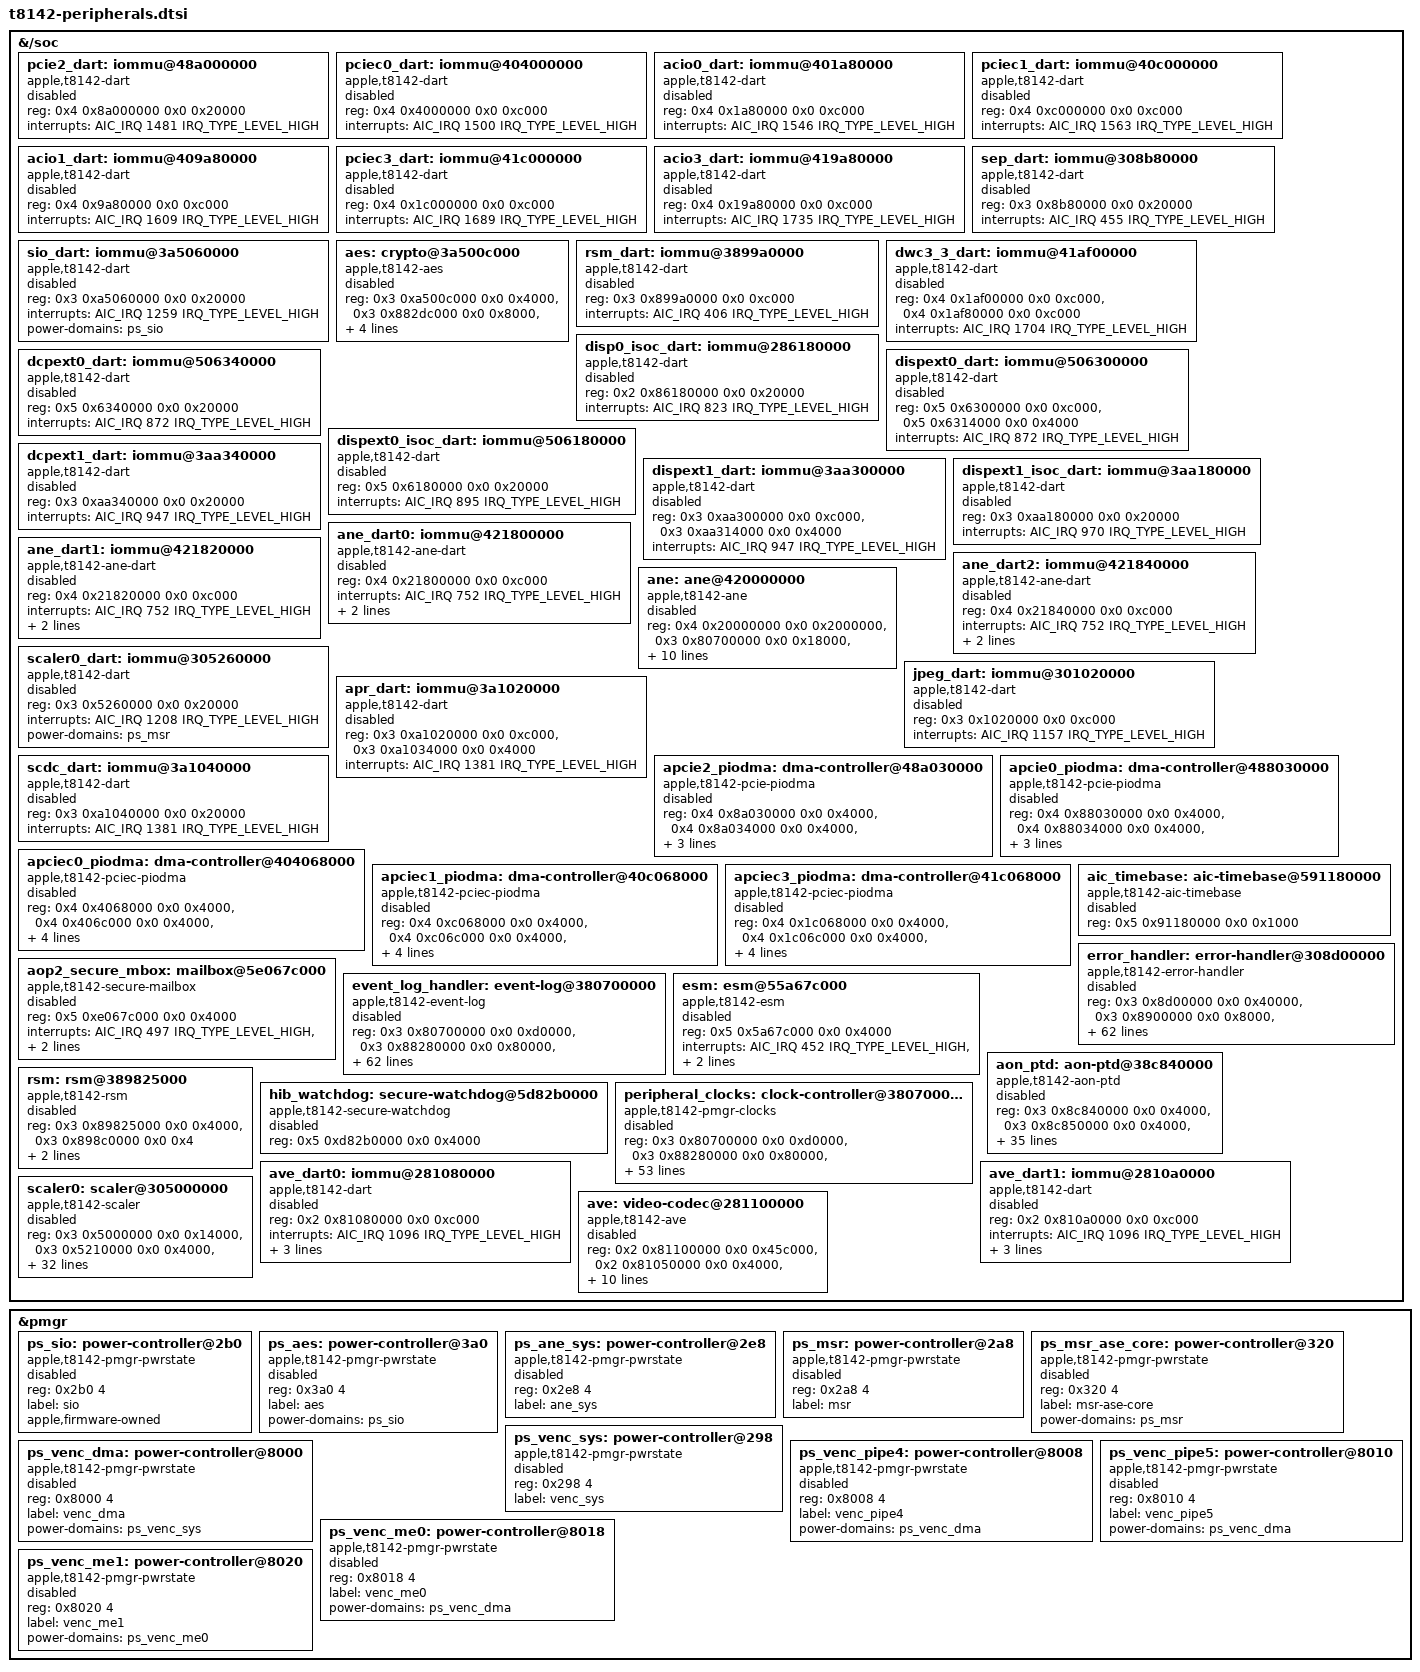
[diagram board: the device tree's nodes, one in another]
// SPDX-License-Identifier: GPL-2.0+ OR MIT
/* Shared SoC resources; firmware ownership and enables need qualification. */

&{/soc} {
	pcie2_dart: iommu@48a000000 {
		compatible = "apple,t8142-dart", "apple,t8110-dart";
		reg = <0x4 0x8a000000 0x0 0x20000>;
		interrupts = <AIC_IRQ 1481 IRQ_TYPE_LEVEL_HIGH>;
		#iommu-cells = <1>;
		status = "disabled";
	};

	pciec0_dart: iommu@404000000 {
		compatible = "apple,t8142-dart", "apple,t8110-dart";
		reg = <0x4 0x4000000 0x0 0xc000>;
		interrupts = <AIC_IRQ 1500 IRQ_TYPE_LEVEL_HIGH>;
		#iommu-cells = <1>;
		status = "disabled";
	};

	acio0_dart: iommu@401a80000 {
		compatible = "apple,t8142-dart", "apple,t8110-dart";
		reg = <0x4 0x1a80000 0x0 0xc000>;
		interrupts = <AIC_IRQ 1546 IRQ_TYPE_LEVEL_HIGH>;
		#iommu-cells = <1>;
		status = "disabled";
	};

	pciec1_dart: iommu@40c000000 {
		compatible = "apple,t8142-dart", "apple,t8110-dart";
		reg = <0x4 0xc000000 0x0 0xc000>;
		interrupts = <AIC_IRQ 1563 IRQ_TYPE_LEVEL_HIGH>;
		#iommu-cells = <1>;
		status = "disabled";
	};

	acio1_dart: iommu@409a80000 {
		compatible = "apple,t8142-dart", "apple,t8110-dart";
		reg = <0x4 0x9a80000 0x0 0xc000>;
		interrupts = <AIC_IRQ 1609 IRQ_TYPE_LEVEL_HIGH>;
		#iommu-cells = <1>;
		status = "disabled";
	};

	pciec3_dart: iommu@41c000000 {
		compatible = "apple,t8142-dart", "apple,t8110-dart";
		reg = <0x4 0x1c000000 0x0 0xc000>;
		interrupts = <AIC_IRQ 1689 IRQ_TYPE_LEVEL_HIGH>;
		#iommu-cells = <1>;
		status = "disabled";
	};

	acio3_dart: iommu@419a80000 {
		compatible = "apple,t8142-dart", "apple,t8110-dart";
		reg = <0x4 0x19a80000 0x0 0xc000>;
		interrupts = <AIC_IRQ 1735 IRQ_TYPE_LEVEL_HIGH>;
		#iommu-cells = <1>;
		status = "disabled";
	};

	sep_dart: iommu@308b80000 {
		compatible = "apple,t8142-dart", "apple,t8110-dart";
		reg = <0x3 0x8b80000 0x0 0x20000>;
		interrupts = <AIC_IRQ 455 IRQ_TYPE_LEVEL_HIGH>;
		#iommu-cells = <1>;
		status = "disabled";
	};

	sio_dart: iommu@3a5060000 {
		compatible = "apple,t8142-dart", "apple,t8110-dart";
		reg = <0x3 0xa5060000 0x0 0x20000>;
		interrupts = <AIC_IRQ 1259 IRQ_TYPE_LEVEL_HIGH>;
		#iommu-cells = <1>;
		power-domains = <&ps_sio>;
		status = "disabled";
	};

	/*
	 * ADT /arm-io/aes (aes,s8000, aes-version 5): the engine, shared control
	 * and auxiliary control windows; DART-SIO mapper-aes is stream 1.
	 */
	aes: crypto@3a500c000 {
		compatible = "apple,t8142-aes", "apple,aes";
		reg = <0x3 0xa500c000 0x0 0x4000>,
		      <0x3 0x882dc000 0x0 0x8000>,
		      <0x3 0x88078000 0x0 0x4000>;
		interrupts = <AIC_IRQ 1246 IRQ_TYPE_LEVEL_HIGH>;
		power-domains = <&ps_aes>;
		iommus = <&sio_dart 1>;
		status = "disabled";
	};

	rsm_dart: iommu@3899a0000 {
		compatible = "apple,t8142-dart", "apple,t8110-dart";
		reg = <0x3 0x899a0000 0x0 0xc000>;
		interrupts = <AIC_IRQ 406 IRQ_TYPE_LEVEL_HIGH>;
		#iommu-cells = <1>;
		status = "disabled";
	};

	dwc3_3_dart: iommu@41af00000 {
		compatible = "apple,t8142-dart", "apple,t8110-dart";
		reg = <0x4 0x1af00000 0x0 0xc000>,
		      <0x4 0x1af80000 0x0 0xc000>;
		interrupts = <AIC_IRQ 1704 IRQ_TYPE_LEVEL_HIGH>;
		#iommu-cells = <1>;
		status = "disabled";
	};

	disp0_isoc_dart: iommu@286180000 {
		compatible = "apple,t8142-dart", "apple,t8110-dart";
		reg = <0x2 0x86180000 0x0 0x20000>;
		interrupts = <AIC_IRQ 823 IRQ_TYPE_LEVEL_HIGH>;
		#iommu-cells = <1>;
		status = "disabled";
	};

	dcpext0_dart: iommu@506340000 {
		compatible = "apple,t8142-dart", "apple,t8110-dart";
		reg = <0x5 0x6340000 0x0 0x20000>;
		interrupts = <AIC_IRQ 872 IRQ_TYPE_LEVEL_HIGH>;
		#iommu-cells = <1>;
		status = "disabled";
	};

	dispext0_dart: iommu@506300000 {
		compatible = "apple,t8142-dart", "apple,t8110-dart";
		reg = <0x5 0x6300000 0x0 0xc000>,
		      <0x5 0x6314000 0x0 0x4000>;
		interrupts = <AIC_IRQ 872 IRQ_TYPE_LEVEL_HIGH>;
		#iommu-cells = <1>;
		status = "disabled";
	};

	dispext0_isoc_dart: iommu@506180000 {
		compatible = "apple,t8142-dart", "apple,t8110-dart";
		reg = <0x5 0x6180000 0x0 0x20000>;
		interrupts = <AIC_IRQ 895 IRQ_TYPE_LEVEL_HIGH>;
		#iommu-cells = <1>;
		status = "disabled";
	};

	dcpext1_dart: iommu@3aa340000 {
		compatible = "apple,t8142-dart", "apple,t8110-dart";
		reg = <0x3 0xaa340000 0x0 0x20000>;
		interrupts = <AIC_IRQ 947 IRQ_TYPE_LEVEL_HIGH>;
		#iommu-cells = <1>;
		status = "disabled";
	};

	dispext1_dart: iommu@3aa300000 {
		compatible = "apple,t8142-dart", "apple,t8110-dart";
		reg = <0x3 0xaa300000 0x0 0xc000>,
		      <0x3 0xaa314000 0x0 0x4000>;
		interrupts = <AIC_IRQ 947 IRQ_TYPE_LEVEL_HIGH>;
		#iommu-cells = <1>;
		status = "disabled";
	};

	dispext1_isoc_dart: iommu@3aa180000 {
		compatible = "apple,t8142-dart", "apple,t8110-dart";
		reg = <0x3 0xaa180000 0x0 0x20000>;
		interrupts = <AIC_IRQ 970 IRQ_TYPE_LEVEL_HIGH>;
		#iommu-cells = <1>;
		status = "disabled";
	};

	/*
	 * The Neural Engine's three DARTs (ADT dart-ane, one interrupt for all):
	 * revision 0x204, 16 streams; SIDs 1-7 are the exclave's and 10/13
	 * bypass. The cold profile leaves every inherited stream alone and
	 * gives the kernel only SID0.
	 */
	ane_dart0: iommu@421800000 {
		compatible = "apple,t8142-ane-dart", "apple,t8142-dart",
			     "apple,t8110-dart";
		reg = <0x4 0x21800000 0x0 0xc000>;
		#iommu-cells = <1>;
		interrupts = <AIC_IRQ 752 IRQ_TYPE_LEVEL_HIGH>;
		power-domains = <&ps_ane_sys>;
		/* The firmware DVAs reach 0x100_xxxx_xxxx. */
		apple,dma-range = <0x0 0x0 0x400 0x0>;
		status = "disabled";
	};

	ane_dart1: iommu@421820000 {
		compatible = "apple,t8142-ane-dart", "apple,t8142-dart",
			     "apple,t8110-dart";
		reg = <0x4 0x21820000 0x0 0xc000>;
		#iommu-cells = <1>;
		interrupts = <AIC_IRQ 752 IRQ_TYPE_LEVEL_HIGH>;
		power-domains = <&ps_ane_sys>;
		apple,dma-range = <0x0 0x0 0x400 0x0>;
		status = "disabled";
	};

	ane_dart2: iommu@421840000 {
		compatible = "apple,t8142-ane-dart", "apple,t8142-dart",
			     "apple,t8110-dart";
		reg = <0x4 0x21840000 0x0 0xc000>;
		#iommu-cells = <1>;
		interrupts = <AIC_IRQ 752 IRQ_TYPE_LEVEL_HIGH>;
		power-domains = <&ps_ane_sys>;
		apple,dma-range = <0x0 0x0 0x400 0x0>;
		status = "disabled";
	};

	/*
	 * The Neural Engine (ADT /arm-io/ane, "ane,t8132exclave", ane-type 0x210):
	 * the H17 engine, exclave-assigned, with firmware that iBoot preloads; the
	 * boot loader hands the preload over as firmware-text and firmware-data.
	 * PWGATE is the ADT's reg[2] (PMGR +0x24000) + 0x3640, measured under
	 * macOS 27.2.1.
	 */
	ane: ane@420000000 {
		compatible = "apple,t8142-ane";
		reg = <0x4 0x20000000 0x0 0x2000000>,
		      <0x3 0x80700000 0x0 0x18000>,
		      <0x3 0x80727640 0x0 0x34>;
		reg-names = "engine", "pmgr", "pwgate";
		interrupts = <AIC_IRQ 751 IRQ_TYPE_LEVEL_HIGH>,
			     <AIC_IRQ 764 IRQ_TYPE_LEVEL_HIGH>;
		iommus = <&ane_dart0 0>, <&ane_dart1 0>, <&ane_dart2 0>;
		power-domains = <&ps_ane_sys>;
		apple,firmware-preloaded;
		apple,firmware-iovas = /bits/ 64 <0x10000000000 0x100000c0000>;
		/* Inclusive SID0 identity windows from the ADT's dart-ane dapf-instance-0. */
		apple,dapf-ranges = /bits/ 64 <0x4a1668000 0x4a1668003
					     0x3807002e8 0x3807002eb
					     0x38070c008 0x38070c00b
					     0x582668000 0x582668003>;
		status = "disabled";
	};

	scaler0_dart: iommu@305260000 {
		compatible = "apple,t8142-dart", "apple,t8110-dart";
		reg = <0x3 0x5260000 0x0 0x20000>;
		interrupts = <AIC_IRQ 1208 IRQ_TYPE_LEVEL_HIGH>;
		/* No DART gate in the ADT: powered with its engine. */
		power-domains = <&ps_msr>;
		#iommu-cells = <1>;
		status = "disabled";
	};

	jpeg_dart: iommu@301020000 {
		compatible = "apple,t8142-dart", "apple,t8110-dart";
		reg = <0x3 0x1020000 0x0 0xc000>;
		interrupts = <AIC_IRQ 1157 IRQ_TYPE_LEVEL_HIGH>;
		#iommu-cells = <1>;
		status = "disabled";
	};

	apr_dart: iommu@3a1020000 {
		compatible = "apple,t8142-dart", "apple,t8110-dart";
		reg = <0x3 0xa1020000 0x0 0xc000>,
		      <0x3 0xa1034000 0x0 0x4000>;
		interrupts = <AIC_IRQ 1381 IRQ_TYPE_LEVEL_HIGH>;
		#iommu-cells = <1>;
		status = "disabled";
	};

	scdc_dart: iommu@3a1040000 {
		compatible = "apple,t8142-dart", "apple,t8110-dart";
		reg = <0x3 0xa1040000 0x0 0x20000>;
		interrupts = <AIC_IRQ 1381 IRQ_TYPE_LEVEL_HIGH>;
		#iommu-cells = <1>;
		status = "disabled";
	};

	apcie2_piodma: dma-controller@48a030000 {
		compatible = "apple,t8142-pcie-piodma", "apple,pcie-piodma";
		reg = <0x4 0x8a030000 0x0 0x4000>,
		      <0x4 0x8a034000 0x0 0x4000>,
		      <0x4 0x8a038000 0x0 0x4000>;
		interrupts = <AIC_IRQ 1482 IRQ_TYPE_LEVEL_HIGH>;
		iommus = <&pcie2_dart 17>;
		status = "disabled";
	};

	apcie0_piodma: dma-controller@488030000 {
		compatible = "apple,t8142-pcie-piodma", "apple,pcie-piodma";
		reg = <0x4 0x88030000 0x0 0x4000>,
		      <0x4 0x88034000 0x0 0x4000>,
		      <0x4 0x88038000 0x0 0x4000>;
		interrupts = <AIC_IRQ 1464 IRQ_TYPE_LEVEL_HIGH>;
		iommus = <&pcie0_dart 17>;
		status = "disabled";
	};

	apciec0_piodma: dma-controller@404068000 {
		compatible = "apple,t8142-pciec-piodma", "apple,pciec-piodma";
		reg = <0x4 0x4068000 0x0 0x4000>,
		      <0x4 0x406c000 0x0 0x4000>,
		      <0x4 0x4070000 0x0 0x4000>,
		      <0x4 0x403c000 0x0 0x4000>;
		interrupts = <AIC_IRQ 1501 IRQ_TYPE_LEVEL_HIGH>;
		iommus = <&pciec0_dart 254>;
		status = "disabled";
	};

	apciec1_piodma: dma-controller@40c068000 {
		compatible = "apple,t8142-pciec-piodma", "apple,pciec-piodma";
		reg = <0x4 0xc068000 0x0 0x4000>,
		      <0x4 0xc06c000 0x0 0x4000>,
		      <0x4 0xc070000 0x0 0x4000>,
		      <0x4 0xc03c000 0x0 0x4000>;
		interrupts = <AIC_IRQ 1564 IRQ_TYPE_LEVEL_HIGH>;
		iommus = <&pciec1_dart 254>;
		status = "disabled";
	};

	apciec3_piodma: dma-controller@41c068000 {
		compatible = "apple,t8142-pciec-piodma", "apple,pciec-piodma";
		reg = <0x4 0x1c068000 0x0 0x4000>,
		      <0x4 0x1c06c000 0x0 0x4000>,
		      <0x4 0x1c070000 0x0 0x4000>,
		      <0x4 0x1c03c000 0x0 0x4000>;
		interrupts = <AIC_IRQ 1690 IRQ_TYPE_LEVEL_HIGH>;
		iommus = <&pciec3_dart 254>;
		status = "disabled";
	};

	aic_timebase: aic-timebase@591180000 {
		compatible = "apple,t8142-aic-timebase", "apple,aic-timebase";
		reg = <0x5 0x91180000 0x0 0x1000>;
		status = "disabled";
	};

	error_handler: error-handler@308d00000 {
		compatible = "apple,t8142-error-handler", "apple,soc-error-handler";
		reg = <0x3 0x8d00000 0x0 0x40000>,
		      <0x3 0x8900000 0x0 0x8000>,
		      <0x3 0x80000000 0x0 0x3c000>,
		      <0x3 0x80728000 0x0 0x4000>,
		      <0x3 0x80768000 0x0 0x4000>,
		      <0x3 0x882c8000 0x0 0x4000>,
		      <0x3 0x82000000 0x0 0x1000000>,
		      <0x3 0x803d0000 0x0 0x4000>,
		      <0x2 0x20000000 0x0 0x140000>,
		      <0x2 0x21000000 0x0 0x3c000>,
		      <0x2 0x21200000 0x0 0x3c000>,
		      <0x2 0x21400000 0x0 0x3c000>,
		      <0x2 0x21600000 0x0 0x3c000>,
		      <0x2 0x21800000 0x0 0x3c000>,
		      <0x2 0x21a00000 0x0 0x3c000>,
		      <0x2 0x21c00000 0x0 0x3c000>,
		      <0x2 0x21e00000 0x0 0x3c000>,
		      <0x2 0x4f000000 0x0 0x8000>,
		      <0x2 0x50000000 0x0 0x8000>,
		      <0x2 0x51000000 0x0 0x8000>,
		      <0x2 0x52000000 0x0 0x8000>,
		      <0x2 0x53000000 0x0 0x8000>,
		      <0x2 0x54000000 0x0 0x8000>,
		      <0x2 0x55000000 0x0 0x8000>,
		      <0x2 0x56000000 0x0 0x8000>,
		      <0x2 0x5f000000 0x0 0x8000>,
		      <0x2 0x6f000000 0x0 0x8000>,
		      <0x2 0x57000000 0x0 0x1000000>,
		      <0x2 0x58000000 0x0 0x1000000>,
		      <0x2 0x59000000 0x0 0x1000000>,
		      <0x3 0x80770000 0x0 0x4000>,
		      <0x3 0x80771000 0x0 0x4000>,
		      <0x2 0x5b000000 0x0 0x24000>;
		interrupts = <AIC_IRQ 454 IRQ_TYPE_LEVEL_HIGH>,
		             <AIC_IRQ 457 IRQ_TYPE_LEVEL_HIGH>,
		             <AIC_IRQ 453 IRQ_TYPE_LEVEL_HIGH>,
		             <AIC_IRQ 1069 IRQ_TYPE_LEVEL_HIGH>,
		             <AIC_IRQ 371 IRQ_TYPE_LEVEL_HIGH>,
		             <AIC_IRQ 373 IRQ_TYPE_LEVEL_HIGH>,
		             <AIC_IRQ 375 IRQ_TYPE_LEVEL_HIGH>,
		             <AIC_IRQ 377 IRQ_TYPE_LEVEL_HIGH>,
		             <AIC_IRQ 379 IRQ_TYPE_LEVEL_HIGH>,
		             <AIC_IRQ 382 IRQ_TYPE_LEVEL_HIGH>,
		             <AIC_IRQ 385 IRQ_TYPE_LEVEL_HIGH>,
		             <AIC_IRQ 388 IRQ_TYPE_LEVEL_HIGH>,
		             <AIC_IRQ 391 IRQ_TYPE_LEVEL_HIGH>,
		             <AIC_IRQ 394 IRQ_TYPE_LEVEL_HIGH>,
		             <AIC_IRQ 397 IRQ_TYPE_LEVEL_HIGH>,
		             <AIC_IRQ 400 IRQ_TYPE_LEVEL_HIGH>,
		             <AIC_IRQ 187 IRQ_TYPE_LEVEL_HIGH>,
		             <AIC_IRQ 188 IRQ_TYPE_LEVEL_HIGH>,
		             <AIC_IRQ 189 IRQ_TYPE_LEVEL_HIGH>,
		             <AIC_IRQ 190 IRQ_TYPE_LEVEL_HIGH>,
		             <AIC_IRQ 191 IRQ_TYPE_LEVEL_HIGH>,
		             <AIC_IRQ 192 IRQ_TYPE_LEVEL_HIGH>,
		             <AIC_IRQ 193 IRQ_TYPE_LEVEL_HIGH>,
		             <AIC_IRQ 194 IRQ_TYPE_LEVEL_HIGH>,
		             <AIC_IRQ 201 IRQ_TYPE_LEVEL_HIGH>,
		             <AIC_IRQ 200 IRQ_TYPE_LEVEL_HIGH>,
		             <AIC_IRQ 195 IRQ_TYPE_LEVEL_HIGH>,
		             <AIC_IRQ 196 IRQ_TYPE_LEVEL_HIGH>,
		             <AIC_IRQ 197 IRQ_TYPE_LEVEL_HIGH>,
		             <AIC_IRQ 311 IRQ_TYPE_LEVEL_HIGH>,
		             <AIC_IRQ 198 IRQ_TYPE_LEVEL_HIGH>;
		/* Shared status windows do not grant AP ownership. */
		status = "disabled";
	};

	aop2_secure_mbox: mailbox@5e067c000 {
		compatible = "apple,t8142-secure-mailbox", "apple,secure-mailbox";
		reg = <0x5 0xe067c000 0x0 0x4000>;
		interrupts = <AIC_IRQ 497 IRQ_TYPE_LEVEL_HIGH>,
		             <AIC_IRQ 494 IRQ_TYPE_LEVEL_HIGH>;
		iommus = <&aop_dart 1>;
		status = "disabled";
	};

	event_log_handler: event-log@380700000 {
		compatible = "apple,t8142-event-log", "apple,soc-event-log";
		reg = <0x3 0x80700000 0x0 0xd0000>,
		      <0x3 0x88280000 0x0 0x80000>,
		      <0x3 0x80000000 0x0 0x3c000>,
		      <0x3 0x88200000 0x0 0x2c000>,
		      <0x3 0x8028c000 0x0 0x4000>,
		      <0x3 0x80280000 0x0 0x8000>,
		      <0x4 0x21878000 0x0 0x4000>,
		      <0x4 0x21868000 0x0 0x8000>,
		      <0x3 0x80340000 0x0 0xc000>,
		      <0x3 0x80350000 0x0 0xc000>,
		      <0x3 0x80208000 0x0 0x4000>,
		      <0x3 0x80208400 0x0 0x4000>,
		      <0x3 0x8020a400 0x0 0x4000>,
		      <0x3 0x8020a600 0x0 0x4000>,
		      <0x3 0x8020a700 0x0 0x4000>,
		      <0x3 0x8020a800 0x0 0x4000>,
		      <0x3 0x8020aa00 0x0 0x4000>,
		      <0x3 0x8020ab00 0x0 0x4000>,
		      <0x3 0x8020ac00 0x0 0x4000>,
		      <0x3 0x8020ae00 0x0 0x4000>,
		      <0x3 0x8020af00 0x0 0x4000>,
		      <0x3 0x8020b000 0x0 0x4000>,
		      <0x3 0x8020b200 0x0 0x4000>,
		      <0x3 0x8020b300 0x0 0x4000>,
		      <0x3 0x8020b400 0x0 0x4000>,
		      <0x3 0x8020b600 0x0 0x4000>,
		      <0x3 0x8020b700 0x0 0x4000>,
		      <0x3 0x8020b800 0x0 0x4000>,
		      <0x3 0x8020ba00 0x0 0x4000>,
		      <0x3 0x8020bb00 0x0 0x4000>,
		      <0x3 0x8020bc00 0x0 0x4000>,
		      <0x3 0x8020be00 0x0 0x4000>,
		      <0x3 0x8020bf00 0x0 0x4000>,
		      <0x3 0x8020c000 0x0 0x4000>,
		      <0x3 0x8020c200 0x0 0x4000>,
		      <0x3 0x8020c300 0x0 0x4000>,
		      <0x3 0x8020c400 0x0 0x4000>,
		      <0x3 0x8020c600 0x0 0x4000>,
		      <0x3 0x8020c700 0x0 0x4000>,
		      <0x3 0x8020c800 0x0 0x4000>,
		      <0x3 0x8020ca00 0x0 0x4000>,
		      <0x3 0x8020cb00 0x0 0x4000>,
		      <0x3 0x8020cc00 0x0 0x4000>,
		      <0x3 0x8020ce00 0x0 0x4000>,
		      <0x3 0x8020d000 0x0 0x4000>,
		      <0x3 0x8020d200 0x0 0x4000>,
		      <0x3 0x8020d400 0x0 0x4000>,
		      <0x3 0x8020d600 0x0 0x4000>,
		      <0x3 0x8020d800 0x0 0x4000>,
		      <0x3 0x8020da00 0x0 0x4000>,
		      <0x3 0x82700000 0x0 0x114000>;
		interrupts = <AIC_IRQ 305 IRQ_TYPE_LEVEL_HIGH>,
		             <AIC_IRQ 358 IRQ_TYPE_LEVEL_HIGH>,
		             <AIC_IRQ 345 IRQ_TYPE_LEVEL_HIGH>,
		             <AIC_IRQ 367 IRQ_TYPE_LEVEL_HIGH>,
		             <AIC_IRQ 25 IRQ_TYPE_LEVEL_HIGH>,
		             <AIC_IRQ 26 IRQ_TYPE_LEVEL_HIGH>,
		             <AIC_IRQ 684 IRQ_TYPE_LEVEL_HIGH>,
		             <AIC_IRQ 676 IRQ_TYPE_LEVEL_HIGH>,
		             <AIC_IRQ 313 IRQ_TYPE_LEVEL_HIGH>,
		             <AIC_IRQ 315 IRQ_TYPE_LEVEL_HIGH>,
		             <AIC_IRQ 134 IRQ_TYPE_LEVEL_HIGH>,
		             <AIC_IRQ 1056 IRQ_TYPE_LEVEL_HIGH>,
		             <AIC_IRQ 1142 IRQ_TYPE_LEVEL_HIGH>;
		/* Shared status windows do not grant AP ownership. */
		status = "disabled";
	};

	esm: esm@55a67c000 {
		compatible = "apple,t8142-esm", "apple,esm";
		reg = <0x5 0x5a67c000 0x0 0x4000>;
		interrupts = <AIC_IRQ 452 IRQ_TYPE_LEVEL_HIGH>,
		             <AIC_IRQ 449 IRQ_TYPE_LEVEL_HIGH>;
		iommus = <&sep_dart 2>;
		status = "disabled";
	};

	aon_ptd: aon-ptd@38c840000 {
		compatible = "apple,t8142-aon-ptd", "apple,aon-ptd";
		reg = <0x3 0x8c840000 0x0 0x4000>,
		      <0x3 0x8c850000 0x0 0x4000>,
		      <0x3 0x8c858000 0x0 0x4000>,
		      <0x3 0x8c860000 0x0 0x4000>;
		interrupts = <AIC_IRQ 639 IRQ_TYPE_LEVEL_HIGH>,
		             <AIC_IRQ 640 IRQ_TYPE_LEVEL_HIGH>,
		             <AIC_IRQ 641 IRQ_TYPE_LEVEL_HIGH>,
		             <AIC_IRQ 642 IRQ_TYPE_LEVEL_HIGH>,
		             <AIC_IRQ 643 IRQ_TYPE_LEVEL_HIGH>,
		             <AIC_IRQ 644 IRQ_TYPE_LEVEL_HIGH>,
		             <AIC_IRQ 645 IRQ_TYPE_LEVEL_HIGH>,
		             <AIC_IRQ 646 IRQ_TYPE_LEVEL_HIGH>,
		             <AIC_IRQ 647 IRQ_TYPE_LEVEL_HIGH>,
		             <AIC_IRQ 648 IRQ_TYPE_LEVEL_HIGH>,
		             <AIC_IRQ 649 IRQ_TYPE_LEVEL_HIGH>,
		             <AIC_IRQ 650 IRQ_TYPE_LEVEL_HIGH>,
		             <AIC_IRQ 651 IRQ_TYPE_LEVEL_HIGH>,
		             <AIC_IRQ 652 IRQ_TYPE_LEVEL_HIGH>,
		             <AIC_IRQ 653 IRQ_TYPE_LEVEL_HIGH>,
		             <AIC_IRQ 654 IRQ_TYPE_LEVEL_HIGH>,
		             <AIC_IRQ 655 IRQ_TYPE_LEVEL_HIGH>,
		             <AIC_IRQ 656 IRQ_TYPE_LEVEL_HIGH>,
		             <AIC_IRQ 657 IRQ_TYPE_LEVEL_HIGH>,
		             <AIC_IRQ 658 IRQ_TYPE_LEVEL_HIGH>,
		             <AIC_IRQ 659 IRQ_TYPE_LEVEL_HIGH>,
		             <AIC_IRQ 660 IRQ_TYPE_LEVEL_HIGH>,
		             <AIC_IRQ 661 IRQ_TYPE_LEVEL_HIGH>,
		             <AIC_IRQ 662 IRQ_TYPE_LEVEL_HIGH>,
		             <AIC_IRQ 663 IRQ_TYPE_LEVEL_HIGH>,
		             <AIC_IRQ 664 IRQ_TYPE_LEVEL_HIGH>,
		             <AIC_IRQ 665 IRQ_TYPE_LEVEL_HIGH>,
		             <AIC_IRQ 666 IRQ_TYPE_LEVEL_HIGH>,
		             <AIC_IRQ 667 IRQ_TYPE_LEVEL_HIGH>,
		             <AIC_IRQ 668 IRQ_TYPE_LEVEL_HIGH>,
		             <AIC_IRQ 669 IRQ_TYPE_LEVEL_HIGH>,
		             <AIC_IRQ 670 IRQ_TYPE_LEVEL_HIGH>;
		interrupt-controller;
		#interrupt-cells = <1>;
		#address-cells = <0>;
		status = "disabled";
	};

	rsm: rsm@389825000 {
		compatible = "apple,t8142-rsm", "apple,rsm";
		reg = <0x3 0x89825000 0x0 0x4000>,
		      <0x3 0x898c0000 0x0 0x4>;
		interrupts = <AIC_IRQ 403 IRQ_TYPE_LEVEL_HIGH>;
		iommus = <&rsm_dart 0>;
		status = "disabled";
	};

	hib_watchdog: secure-watchdog@5d82b0000 {
		compatible = "apple,t8142-secure-watchdog", "apple,secure-watchdog";
		reg = <0x5 0xd82b0000 0x0 0x4000>;
		status = "disabled";
	};
};

&pmgr {
	/* ADT pmgr device SIO (id 66). Owned by the firmware that runs the SIO. */
	ps_sio: power-controller@2b0 {
		compatible = "apple,t8142-pmgr-pwrstate", "apple,t8103-pmgr-pwrstate";
		reg = <0x2b0 4>;
		#power-domain-cells = <0>;
		#reset-cells = <0>;
		label = "sio";
		apple,firmware-owned;
		status = "disabled";
	};

	/* ADT pmgr device AES (id 96), the SIO AES engine. */
	ps_aes: power-controller@3a0 {
		compatible = "apple,t8142-pmgr-pwrstate", "apple,t8103-pmgr-pwrstate";
		reg = <0x3a0 4>;
		#power-domain-cells = <0>;
		#reset-cells = <0>;
		label = "aes";
		power-domains = <&ps_sio>;
		status = "disabled";
	};

	/* ADT pmgr device ANE_SYS (id 73), parent AFISOCNI3 (no power state). */
	ps_ane_sys: power-controller@2e8 {
		compatible = "apple,t8142-pmgr-pwrstate", "apple,t8103-pmgr-pwrstate";
		reg = <0x2e8 4>;
		#power-domain-cells = <0>;
		#reset-cells = <0>;
		label = "ane_sys";
		status = "disabled";
	};

	ps_msr: power-controller@2a8 {
		compatible = "apple,t8142-pmgr-pwrstate", "apple,t8103-pmgr-pwrstate";
		reg = <0x2a8 4>;
		#power-domain-cells = <0>;
		#reset-cells = <0>;
		label = "msr";
		status = "disabled";
	};
	ps_msr_ase_core: power-controller@320 {
		compatible = "apple,t8142-pmgr-pwrstate", "apple,t8103-pmgr-pwrstate";
		reg = <0x320 4>;
		#power-domain-cells = <0>;
		#reset-cells = <0>;
		label = "msr-ase-core";
		power-domains = <&ps_msr>;
		status = "disabled";
	};

	/*
	 * The video encoder's power states (J815 ADT pmgr): VENC_SYS (id 63,
	 * parent AFISOCNI0, no power state) feeds VENC_DMA, which feeds the two
	 * pipes and ME0; ME1 sits under ME0. The same tree as one A18 Pro encoder.
	 */
	ps_venc_sys: power-controller@298 {
		compatible = "apple,t8142-pmgr-pwrstate", "apple,t8103-pmgr-pwrstate";
		reg = <0x298 4>;
		#power-domain-cells = <0>;
		#reset-cells = <0>;
		label = "venc_sys";
		status = "disabled";
	};

	ps_venc_dma: power-controller@8000 {
		compatible = "apple,t8142-pmgr-pwrstate", "apple,t8103-pmgr-pwrstate";
		reg = <0x8000 4>;
		#power-domain-cells = <0>;
		#reset-cells = <0>;
		label = "venc_dma";
		power-domains = <&ps_venc_sys>;
		status = "disabled";
	};

	ps_venc_pipe4: power-controller@8008 {
		compatible = "apple,t8142-pmgr-pwrstate", "apple,t8103-pmgr-pwrstate";
		reg = <0x8008 4>;
		#power-domain-cells = <0>;
		#reset-cells = <0>;
		label = "venc_pipe4";
		power-domains = <&ps_venc_dma>;
		status = "disabled";
	};

	ps_venc_pipe5: power-controller@8010 {
		compatible = "apple,t8142-pmgr-pwrstate", "apple,t8103-pmgr-pwrstate";
		reg = <0x8010 4>;
		#power-domain-cells = <0>;
		#reset-cells = <0>;
		label = "venc_pipe5";
		power-domains = <&ps_venc_dma>;
		status = "disabled";
	};

	ps_venc_me0: power-controller@8018 {
		compatible = "apple,t8142-pmgr-pwrstate", "apple,t8103-pmgr-pwrstate";
		reg = <0x8018 4>;
		#power-domain-cells = <0>;
		#reset-cells = <0>;
		label = "venc_me0";
		power-domains = <&ps_venc_dma>;
		status = "disabled";
	};

	ps_venc_me1: power-controller@8020 {
		compatible = "apple,t8142-pmgr-pwrstate", "apple,t8103-pmgr-pwrstate";
		reg = <0x8020 4>;
		#power-domain-cells = <0>;
		#reset-cells = <0>;
		label = "venc_me1";
		power-domains = <&ps_venc_me0>;
		status = "disabled";
	};
};

&{/soc} {
	peripheral_clocks: clock-controller@380700000 {
		compatible = "apple,t8142-pmgr-clocks", "apple,pmgr-clocks";
		reg = <0x3 0x80700000 0x0 0xd0000>,
		      <0x3 0x88280000 0x0 0x80000>,
		      <0x3 0x80000000 0x0 0x3c000>,
		      <0x3 0x88200000 0x0 0x2c000>,
		      <0x3 0x88004000 0x0 0x1000>,
		      <0x2 0x10e20000 0x0 0x1268>,
		      <0x2 0x10f00000 0x0 0x40088>,
		      <0x2 0x10e40000 0x0 0xc020>,
		      <0x2 0x10e50000 0x0 0x9048>,
		      <0x2 0x10e70000 0x0 0xffe8>,
		      <0x2 0x10050000 0x0 0x9010>,
		      <0x2 0x10150000 0x0 0x9010>,
		      <0x2 0x10250000 0x0 0x9010>,
		      <0x2 0x10350000 0x0 0x9010>,
		      <0x2 0x10450000 0x0 0x9010>,
		      <0x2 0x10550000 0x0 0x9010>,
		      <0x2 0x11e20000 0x0 0x12e8>,
		      <0x2 0x11f00000 0x0 0x40088>,
		      <0x2 0x11e40000 0x0 0xc020>,
		      <0x2 0x11e50000 0x0 0x9048>,
		      <0x2 0x11e70000 0x0 0xffe8>,
		      <0x2 0x11050000 0x0 0x9018>,
		      <0x2 0x11150000 0x0 0x9018>,
		      <0x2 0x11250000 0x0 0x9018>,
		      <0x2 0x11350000 0x0 0x9018>,
		      <0x3 0x80280000 0x0 0x8000>,
		      <0x3 0x88700000 0x0 0x4000>,
		      <0x3 0x88100000 0x0 0xa8000>,
		      <0x4 0x2195c000 0x0 0x4000>,
		      <0x4 0x21960000 0x0 0x4000>,
		      <0x4 0x21974000 0x0 0x4000>,
		      <0x3 0x80208000 0x0 0x8000>,
		      <0x3 0x80700000 0x0 0x18000>,
		      <0x3 0x80728000 0x0 0x4000>,
		      <0x3 0x80724000 0x0 0x4000>,
		      <0x3 0x80764000 0x0 0x4000>,
		      <0x3 0x80780000 0x0 0x4000>,
		      <0x3 0x80760000 0x0 0x4000>,
		      <0x3 0x882b8000 0x0 0x10000>,
		      <0x3 0x882c8000 0x0 0x4000>,
		      <0x3 0x882d0000 0x0 0x8000>,
		      <0x3 0x803c0000 0x0 0x20000>,
		      <0x3 0x80730000 0x0 0x14000>,
		      <0x2 0x11000000 0x0 0xff4000>,
		      <0x4 0x21954000 0x0 0x4000>,
		      <0x3 0x80768000 0x0 0x4000>,
		      <0x3 0x8002c000 0x0 0x4000>,
		      <0x3 0x82000000 0x0 0x1000000>,
		      <0x5 0x80e80000 0x0 0x30000>,
		      <0x5 0x80ec0000 0x0 0x4000>,
		      <0x5 0x80ec0000 0x0 0x8000>,
		      <0x5 0x80e30000 0x0 0x4000>,
		      <0x5 0x80e30000 0x0 0x8000>,
		      <0x2 0x10000000 0x0 0xff4000>;
		#clock-cells = <1>;
		apple,pmgr = <&pmgr>;
		status = "disabled";
	};

	/*
	 * The video encoder (ADT ave, "ave2", soc-id t8142): the A18 Pro's
	 * encoder at 0x281000000 instead of 0x285000000. Its firmware is
	 * preloaded by iBoot and handed over by the boot loader, which adds the
	 * memory regions. dart-ave is two DARTs (DART and CPUDART) on one IRQ;
	 * stream 12 carries the temporal filter engines and must translate
	 * through the encoder's domain, not bypass.
	 */
	ave_dart0: iommu@281080000 {
		compatible = "apple,t8142-dart", "apple,t8110-dart";
		reg = <0x2 0x81080000 0x0 0xc000>;
		interrupts = <AIC_IRQ 1096 IRQ_TYPE_LEVEL_HIGH>;
		power-domains = <&ps_venc_sys>;
		#iommu-cells = <1>;
		apple,dma-range = <0x100 0x00004000 0x0 0xffffc000>;
		status = "disabled";
	};

	ave_dart1: iommu@2810a0000 {
		compatible = "apple,t8142-dart", "apple,t8110-dart";
		reg = <0x2 0x810a0000 0x0 0xc000>;
		interrupts = <AIC_IRQ 1096 IRQ_TYPE_LEVEL_HIGH>;
		power-domains = <&ps_venc_sys>;
		#iommu-cells = <1>;
		apple,dma-range = <0x100 0x00004000 0x0 0xffffc000>;
		status = "disabled";
	};

	ave: video-codec@281100000 {
		compatible = "apple,t8142-ave";
		reg = <0x2 0x81100000 0x0 0x45c000>,
		      <0x2 0x81050000 0x0 0x4000>,
		      <0x2 0x81800000 0x0 0x800000>;
		reg-names = "codec", "mailbox", "coproc";
		interrupts = <AIC_IRQ 1099 IRQ_TYPE_LEVEL_HIGH>,
			     <AIC_IRQ 1093 IRQ_TYPE_LEVEL_HIGH>,
			     <AIC_IRQ 1092 IRQ_TYPE_LEVEL_HIGH>,
			     <AIC_IRQ 1095 IRQ_TYPE_LEVEL_HIGH>,
			     <AIC_IRQ 1094 IRQ_TYPE_LEVEL_HIGH>;
		power-domains = <&ps_venc_dma>, <&ps_venc_pipe4>,
				<&ps_venc_pipe5>, <&ps_venc_me0>, <&ps_venc_me1>;
		power-domain-names = "dma", "pipe4", "pipe5", "me0", "me1";
		iommus = <&ave_dart0 0>, <&ave_dart0 12>,
			 <&ave_dart1 0>, <&ave_dart1 12>;
		status = "disabled";
	};

	scaler0: scaler@305000000 {
		compatible = "apple,t8142-scaler", "apple,scaler-v23";
		reg = <0x3 0x5000000 0x0 0x14000>,
		      <0x3 0x5210000 0x0 0x4000>,
		      <0x3 0x5204000 0x0 0x4000>,
		      <0x3 0x4000000 0x0 0x8000>,
		      <0x3 0x52c0000 0x0 0x40000>,
		      <0x3 0x5340000 0x0 0x14c000>,
		      <0x3 0x52a0000 0x0 0x4000>,
		      <0x3 0x5208000 0x0 0x4000>,
		      <0x3 0x5210000 0x0 0x4000>,
		      <0x3 0x5220000 0x0 0x4000>;
		interrupts = <AIC_IRQ 1207 IRQ_TYPE_LEVEL_HIGH>,
		             <AIC_IRQ 1209 IRQ_TYPE_LEVEL_HIGH>,
		             <AIC_IRQ 1210 IRQ_TYPE_LEVEL_HIGH>,
		             <AIC_IRQ 1211 IRQ_TYPE_LEVEL_HIGH>,
		             <AIC_IRQ 1215 IRQ_TYPE_LEVEL_HIGH>,
		             <AIC_IRQ 1216 IRQ_TYPE_LEVEL_HIGH>,
		             <AIC_IRQ 1217 IRQ_TYPE_LEVEL_HIGH>,
		             <AIC_IRQ 1218 IRQ_TYPE_LEVEL_HIGH>,
		             <AIC_IRQ 1219 IRQ_TYPE_LEVEL_HIGH>,
		             <AIC_IRQ 1220 IRQ_TYPE_LEVEL_HIGH>,
		             <AIC_IRQ 1221 IRQ_TYPE_LEVEL_HIGH>,
		             <AIC_IRQ 1222 IRQ_TYPE_LEVEL_HIGH>,
		             <AIC_IRQ 1223 IRQ_TYPE_LEVEL_HIGH>,
		             <AIC_IRQ 1224 IRQ_TYPE_LEVEL_HIGH>,
		             <AIC_IRQ 1225 IRQ_TYPE_LEVEL_HIGH>,
		             <AIC_IRQ 1226 IRQ_TYPE_LEVEL_HIGH>,
		             <AIC_IRQ 1227 IRQ_TYPE_LEVEL_HIGH>,
		             <AIC_IRQ 1228 IRQ_TYPE_LEVEL_HIGH>,
		             <AIC_IRQ 1229 IRQ_TYPE_LEVEL_HIGH>,
		             <AIC_IRQ 1230 IRQ_TYPE_LEVEL_HIGH>;
		iommus = <&scaler0_dart 0>, <&scaler0_dart 1>;
		clocks = <&peripheral_clocks 399>;
		power-domains = <&ps_msr>, <&ps_msr_ase_core>;
		resets = <&ps_msr>;
		status = "disabled";
	};
};
